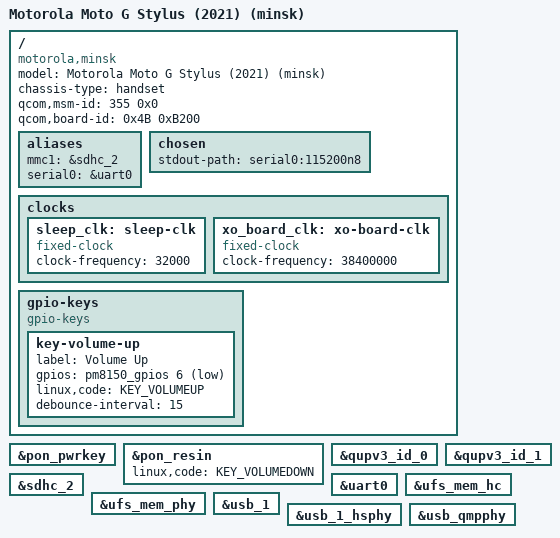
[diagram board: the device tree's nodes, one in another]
// SPDX-License-Identifier: GPL-2.0-only
/dts-v1/;

#include <dt-bindings/gpio/gpio.h>
#include <dt-bindings/input/input.h>
#include <dt-bindings/regulator/qcom,rpmh-regulator.h>
#include "talos.dtsi"
#include "pm8150.dtsi"

/ {
	model = "Motorola Moto G Stylus (2021) (minsk)";
	compatible = "motorola,minsk", "qcom,sm6150";
	chassis-type = "handset";
	qcom,msm-id = <355 0x0>;
	qcom,board-id = <0x4B 0xB200>;

	aliases {
		mmc1 = &sdhc_2;
		serial0 = &uart0;
	};

	chosen {
		stdout-path = "serial0:115200n8";
	};

	clocks {
		sleep_clk: sleep-clk {
			compatible = "fixed-clock";
			clock-frequency = <32000>;
			#clock-cells = <0>;
		};

		xo_board_clk: xo-board-clk {
			compatible = "fixed-clock";
			clock-frequency = <38400000>;
			#clock-cells = <0>;
		};
	};

	gpio-keys {
		compatible = "gpio-keys";

		key-volume-up {
			label = "Volume Up";
			gpios = <&pm8150_gpios 6 GPIO_ACTIVE_LOW>;
			linux,code = <KEY_VOLUMEUP>;
			debounce-interval = <15>;
		};
	};
};

&pon_pwrkey {
	status = "okay";
};

&pon_resin {
	linux,code = <KEY_VOLUMEDOWN>;
	status = "okay";
};

&qupv3_id_0 {
	status = "okay";
};

&qupv3_id_1 {
	status = "okay";
};

&sdhc_2 {
	status = "okay";
};

&uart0 {
	status = "okay";
};

&ufs_mem_hc {
	status = "okay";
};

&ufs_mem_phy {
	status = "okay";
};

&usb_1 {
	status = "okay";
};

&usb_1_hsphy {
	status = "okay";
};

&usb_qmpphy {
	status = "okay";
};
